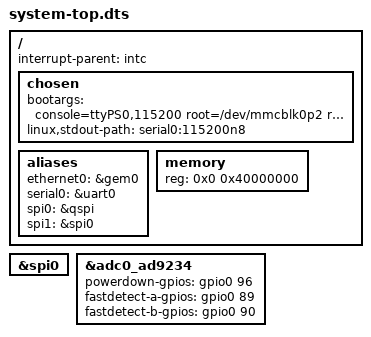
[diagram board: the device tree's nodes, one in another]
/*
 * CAUTION: This file is automatically generated by Xilinx.
 * Version:  
 * Today is: Thu Oct 11 09:51:08 2018
 */


/dts-v1/;
/include/ "zynq-7000.dtsi"

&spi0 {
	status = "okay";
};

#define fmc_spi spi0
#include "daqles.dtsi"

/include/ "pl.dtsi"
/include/ "pcw.dtsi"


/ {
	interrupt-parent = <&intc>;

	chosen {
		bootargs = "console=ttyPS0,115200 root=/dev/mmcblk0p2 rw earlyprintk rootfstype=ext4 rootwait";
		linux,stdout-path = "serial0:115200n8";
	};
	aliases {
		ethernet0 = &gem0;
		serial0 = &uart0;
		spi0 = &qspi;
		spi1 = &spi0;
	};
	memory {
		device_type = "memory";
		reg = <0x0 0x40000000>;
	};
};

&adc0_ad9234 {							// EMIO = X + 54
	powerdown-gpios = <&gpio0 96 0>;   	// hdl 42
	fastdetect-a-gpios = <&gpio0 89 0>;	// hdl 35
	fastdetect-b-gpios = <&gpio0 90 0>;	// hdl 36
};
